VERSION "created by canmatrix"

NS_ :

BS_:

BU_:

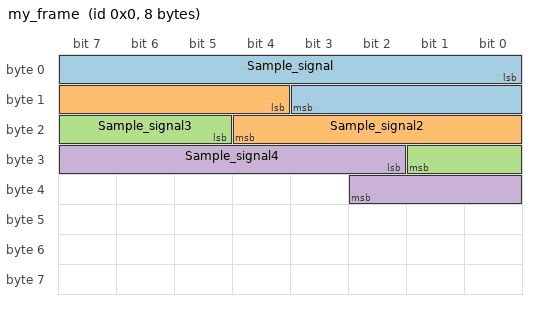
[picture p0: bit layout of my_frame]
BO_ 0 my_frame: 8 Vector__XXX
 SG_ Sample_signal : 0|12@1- (1,0) [-2048|2047] "" Vector__XXX
 SG_ Sample_signal2 : 12|9@1- (1,0) [-256|255] "" Vector__XXX
 SG_ Sample_signal3 : 21|5@1- (1,0) [-16|15] "" Vector__XXX
 SG_ Sample_signal4 : 26|9@1- (1,0) [-256|255] "" Vector__XXX
